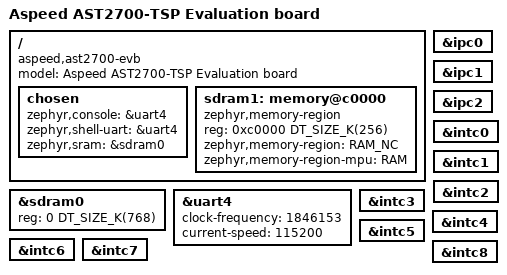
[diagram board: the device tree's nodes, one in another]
/*
 * Copyright (c) 2023 Aspeed Technology Inc.
 *
 * SPDX-License-Identifier: Apache-2.0
 */

/dts-v1/;
#include <aspeed/ast27x0_tsp.dtsi>

/ {
	model = "Aspeed AST2700-TSP Evaluation board";
	compatible = "aspeed,ast2700-evb";

	chosen {
		zephyr,console = &uart4;
		zephyr,shell-uart = &uart4;
		zephyr,sram = &sdram0;
	};

	sdram1: memory@c0000 {
		compatible = "zephyr,memory-region", "mmio-dram";
		device_type = "memory";
		reg = <0xc0000 DT_SIZE_K(256)>;
		zephyr,memory-region = "RAM_NC";
		zephyr,memory-region-mpu = "RAM";
	};
};

&sdram0 {
	reg = <0 DT_SIZE_K(768)>;
};

&uart4 {
	clock-frequency = <1846153>;
	current-speed = <115200>;
	status = "okay";
};

&ipc0 {
	status = "okay";
};

&ipc1 {
	status = "okay";
};

&ipc2 {
	status = "okay";
};

&intc0 {
	status = "okay";
};

&intc1 {
	status = "okay";
};

&intc2 {
	status = "okay";
};

&intc3 {
	status = "okay";
};

&intc4 {
	status = "okay";
};

&intc5 {
	status = "okay";
};

&intc6 {
	status = "okay";
};

&intc7 {
	status = "okay";
};

&intc8 {
	status = "okay";
};
